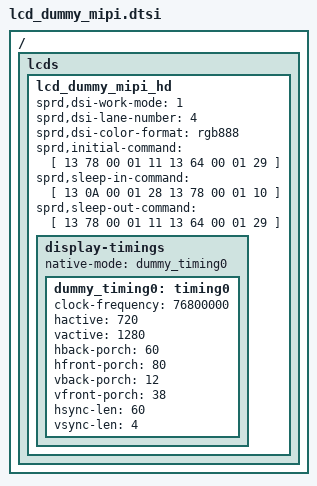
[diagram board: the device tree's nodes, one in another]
// SPDX-License-Identifier: GPL-2.0-only
/*
 * Unisoc Dummy LCD config DTS file
 *
 * Copyright (C) 2021, Unisoc Inc.
 */
/ {
	fragment {
		target-path = "/";
		__overlay__ {
			lcds {
				lcd_dummy_mipi_hd: lcd_dummy_mipi_hd {

					sprd,dsi-work-mode = <1>; /* video burst mode*/
					sprd,dsi-lane-number = <4>;
					sprd,dsi-color-format = "rgb888";

					sprd,initial-command = [
						13 78 00 01 11
						13 64 00 01 29
						];
					sprd,sleep-in-command = [
						13 0A 00 01 28
						13 78 00 01 10
						];
					sprd,sleep-out-command = [
						13 78 00 01 11
						13 64 00 01 29
						];

					display-timings {
						native-mode = <&dummy_timing0>;

						dummy_timing0: timing0 {
							clock-frequency = <76800000>;
							hactive = <720>;
							vactive = <1280>;
							hback-porch = <60>;
							hfront-porch = <80>;
							vback-porch = <12>;
							vfront-porch = <38>;
							hsync-len = <60>;
							vsync-len = <4>;
						};
					};
				};
			};
		};
	};
};
